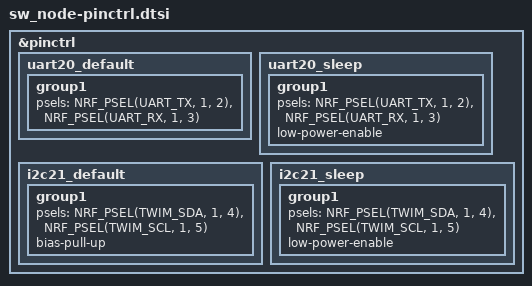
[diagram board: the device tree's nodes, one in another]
/*
 * Smart Wagon sub-node pin control. Common to all 19 nodes - the per-node
 * differences (door reeds, RTD channel) live in each application's app.overlay.
 *
 * Checked against DOCS/Schematic/2.DOOR_Subnode_Schematic.pdf and
 * 3.Tank_Temperature_Subnode_Schematic.pdf.
 *
 * SPDX-License-Identifier: Apache-2.0
 */

&pinctrl {
	/* Debug header D_TX / D_RX. NFC pins, released by &uicr in the .dts. */
	uart20_default: uart20_default {
		group1 {
			psels = <NRF_PSEL(UART_TX, 1, 2)>,
				<NRF_PSEL(UART_RX, 1, 3)>;
		};
	};

	uart20_sleep: uart20_sleep {
		group1 {
			psels = <NRF_PSEL(UART_TX, 1, 2)>,
				<NRF_PSEL(UART_RX, 1, 3)>;
			low-power-enable;
		};
	};

	/* BMA400 (0x14) + STS4x on the switched VCC_AXI rail. */
	i2c21_default: i2c21_default {
		group1 {
			psels = <NRF_PSEL(TWIM_SDA, 1, 4)>,
				<NRF_PSEL(TWIM_SCL, 1, 5)>;
			bias-pull-up;
		};
	};

	i2c21_sleep: i2c21_sleep {
		group1 {
			psels = <NRF_PSEL(TWIM_SDA, 1, 4)>,
				<NRF_PSEL(TWIM_SCL, 1, 5)>;
			low-power-enable;
		};
	};
};
